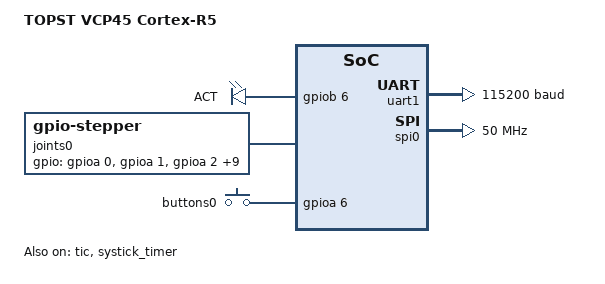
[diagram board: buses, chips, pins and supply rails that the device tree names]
/*
 * Copyright 2024 Hounjoung Rim <hounjoung@tsnlab.com>
 *
 * SPDX-License-Identifier: Apache-2.0
 */

/dts-v1/;

#include <arm/tcc/tcc70xx.dtsi>
#include <arm/tcc/tcc7045.dtsi>
#include <zephyr/dt-bindings/gpio/gpio.h>
#include <zephyr/dt-bindings/spi/spi.h>

/ {
	compatible = "tcc,topst_vcc45";
	model = "TOPST VCP45 Cortex-R5";

	aliases {
		led0 = &led_act;
		spi0 = &spi0;
		buttons0 = &buttons0;
		joints0 = &joints0;
	};

	chosen {
		zephyr,sram = &ram_dlm;
		zephyr,flash = &flash0;
		zephyr,console = &uart1;
		zephyr,shell-uart = &uart1;
	};

	leds {
		compatible = "gpio-leds";

		led_act: led-act {
			gpios = <&gpiob 6 GPIO_ACTIVE_HIGH>;
			label = "ACT";
		};
	};

	joints0: joints0 {
		compatible = "zephyr,gpio-stepper";

		gpios = <&gpioa 0 GPIO_ACTIVE_HIGH>, // joint 1 pulse
				<&gpioa 1 GPIO_ACTIVE_HIGH>, // joint 1 direction

				<&gpioa 2 GPIO_ACTIVE_HIGH>, // joint 2 pulse
				<&gpioa 3 GPIO_ACTIVE_HIGH>, // joint 2 direction

				<&gpioa 4 GPIO_ACTIVE_HIGH>, // joint 3 pulse
				<&gpioa 5 GPIO_ACTIVE_HIGH>, // joint 3 direction

				<&gpioa 8 GPIO_ACTIVE_HIGH>, // joint 4 pulse
				<&gpioa 9 GPIO_ACTIVE_HIGH>, // joint 4 direction

				<&gpioa 10 GPIO_ACTIVE_HIGH>, // joint 5 pulse
				<&gpioa 11 GPIO_ACTIVE_HIGH>, // joint 5 direction

				<&gpioa 16 GPIO_ACTIVE_HIGH>, // joint 6 pulse
				<&gpioa 17 GPIO_ACTIVE_HIGH>; // joint 6 direction
	};

	buttons: buttons {
		compatible = "gpio-keys";

		buttons0: buttons0 {
			gpios = <&gpioa 6 GPIO_ACTIVE_HIGH>,  // joint 1 limit button
					<&gpioa 7 GPIO_ACTIVE_HIGH>,  // joint 2 limit button
					<&gpioa 28 GPIO_ACTIVE_HIGH>, // joint 3 limit button
					<&gpioa 29 GPIO_ACTIVE_HIGH>, // joint 4 limit button
					<&gpiob 3 GPIO_ACTIVE_HIGH>,  // joint 5 limit button
					<&gpiob 2 GPIO_ACTIVE_HIGH>;  // joint 6 limit button
		};
	};
};

&flash0 {
	status = "okay";
};

&gpioa {
	status = "okay";
};

&gpiob {
	status = "okay";
};

&sysclk {
	status = "okay";
};

&tic {
	status = "okay";
};

&systick_timer {
	status = "okay";
	clock-frequency = <12000000>;
};

&uart1 {
	status = "okay";
	current-speed = <115200>;
	clock-frequency = <48000000>;
};

&spi0 {
	status = "okay";
	clock-frequency = <50000000>;
};
